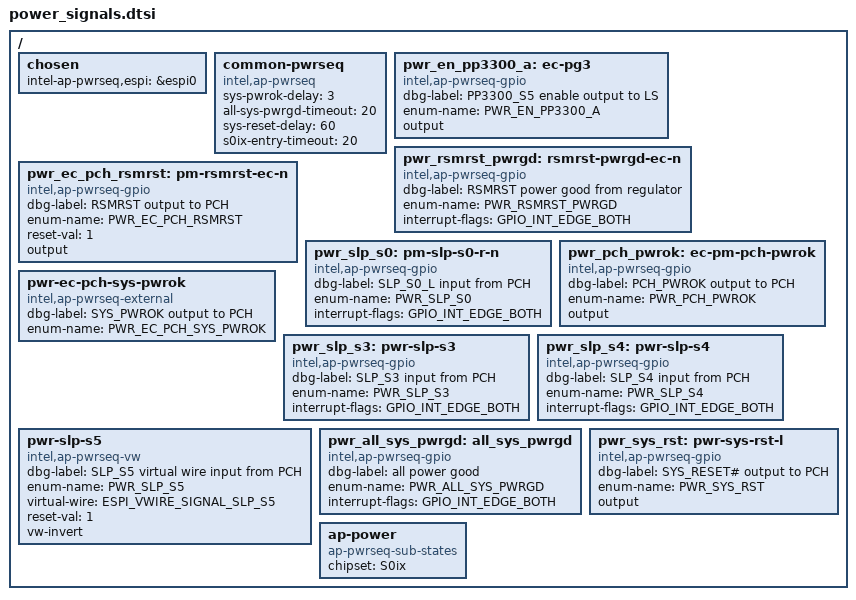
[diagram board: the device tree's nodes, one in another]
/* Copyright 2026 The ChromiumOS Authors
 * Use of this source code is governed by a BSD-style license that can be
 * found in the LICENSE file.
 */

/* This file fundamentally describes the power sequencing signals for the NVL
 * platform and should be included by all atria projects. Each individual
 * project should have its own .dtsi file to assign EC I/O pins to these
 * signals.
 */

/ {
	chosen {
		intel-ap-pwrseq,espi = &espi0;
	};

	common-pwrseq {
		compatible = "intel,ap-pwrseq";

		sys-pwrok-delay = <3>;
		all-sys-pwrgd-timeout = <20>;
		sys-reset-delay = <60>;
		s0ix-entry-timeout = <20>;
	};

	pwr_en_pp3300_a: ec-pg3 {
		compatible = "intel,ap-pwrseq-gpio";
		dbg-label = "PP3300_S5 enable output to LS";
		enum-name = "PWR_EN_PP3300_A";
		/* Note - gpios property must be set by the board overlay */
		output;
	};
	pwr_rsmrst_pwrgd: rsmrst-pwrgd-ec-n {
		compatible = "intel,ap-pwrseq-gpio";
		dbg-label = "RSMRST power good from regulator";
		enum-name = "PWR_RSMRST_PWRGD";
		/* Note - gpios property must be set by the board overlay */
		interrupt-flags = <GPIO_INT_EDGE_BOTH>;
	};
	pwr_ec_pch_rsmrst: pm-rsmrst-ec-n {
		compatible = "intel,ap-pwrseq-gpio";
		dbg-label = "RSMRST output to PCH";
		enum-name = "PWR_EC_PCH_RSMRST";
		/* Note - gpios property must be set by the board overlay */
		reset-val = <1>;
		output;
	};
	pwr_slp_s0: pm-slp-s0-r-n {
		compatible = "intel,ap-pwrseq-gpio";
		dbg-label = "SLP_S0_L input from PCH";
		enum-name = "PWR_SLP_S0";
		/* Note - gpios property must be set by the board overlay */
		interrupt-flags = <GPIO_INT_EDGE_BOTH>;
	};
	pwr_pch_pwrok: ec-pm-pch-pwrok {
		compatible = "intel,ap-pwrseq-gpio";
		dbg-label = "PCH_PWROK output to PCH";
		enum-name = "PWR_PCH_PWROK";
		/* Note - gpios property must be set by the board overlay */
		output;
	};
	pwr-ec-pch-sys-pwrok {
		compatible = "intel,ap-pwrseq-external";
		dbg-label = "SYS_PWROK output to PCH";
		enum-name = "PWR_EC_PCH_SYS_PWROK";
	};
	pwr_slp_s3: pwr-slp-s3 {
		compatible = "intel,ap-pwrseq-gpio";
		dbg-label = "SLP_S3 input from PCH";
		enum-name = "PWR_SLP_S3";
		interrupt-flags = <GPIO_INT_EDGE_BOTH>;
	};
	pwr_slp_s4: pwr-slp-s4 {
		compatible = "intel,ap-pwrseq-gpio";
		dbg-label = "SLP_S4 input from PCH";
		enum-name = "PWR_SLP_S4";
		interrupt-flags = <GPIO_INT_EDGE_BOTH>;
	};
	pwr-slp-s5 {
		compatible = "intel,ap-pwrseq-vw";
		dbg-label = "SLP_S5 virtual wire input from PCH";
		enum-name = "PWR_SLP_S5";
		virtual-wire = "ESPI_VWIRE_SIGNAL_SLP_S5";
		reset-val = <1>;
		vw-invert;
	};
	pwr_all_sys_pwrgd: all_sys_pwrgd {
		compatible = "intel,ap-pwrseq-gpio";
		dbg-label = "all power good";
		enum-name = "PWR_ALL_SYS_PWRGD";
		/* Note - gpios property must be set by the board overlay */
		interrupt-flags = <GPIO_INT_EDGE_BOTH>;
	};
	pwr_sys_rst: pwr-sys-rst-l {
		compatible = "intel,ap-pwrseq-gpio";
		dbg-label = "SYS_RESET# output to PCH";
		enum-name = "PWR_SYS_RST";
		output;
	};
	ap-power {
		compatible = "ap-pwrseq-sub-states";
		chipset = "S0ix";
        };

};
